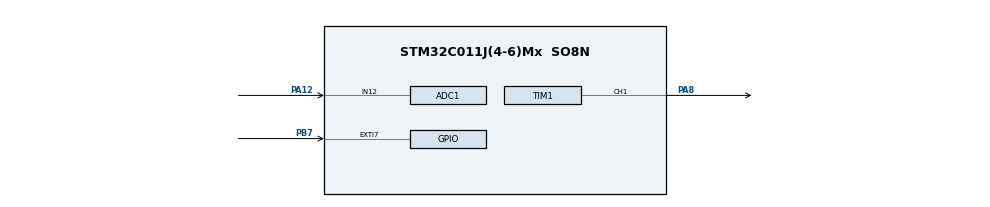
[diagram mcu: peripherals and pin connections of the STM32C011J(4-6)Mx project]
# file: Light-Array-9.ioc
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ADC1.Channel-1\#ChannelRegularConversion=ADC_CHANNEL_12
ADC1.ClockPrescaler=ADC_CLOCK_ASYNC_DIV16
ADC1.ContinuousConvMode=DISABLE
ADC1.DMAContinuousRequests=DISABLE
ADC1.NbrOfConversionFlag=1
ADC1.OffsetNumber-1\#ChannelRegularConversion=ADC_OFFSET_NONE
ADC1.Rank-1\#ChannelRegularConversion=1
ADC1.Resolution=ADC_RESOLUTION_8B
ADC1.SamplingTime-1\#ChannelRegularConversion=ADC_SAMPLINGTIME_COMMON_1
ADC1.SelectedChannel=ADC_CHANNEL_12
ADC1.Sequencer=FULLY_CONFIGURABLE
ADC1.master=1
Dma.Request0=TIM1_CH1
Dma.TIM1_CH1.0.Direction=DMA_MEMORY_TO_PERIPH
Dma.TIM1_CH1.0.EventEnable=DISABLE
Dma.TIM1_CH1.0.Instance=DMA1_Channel1
Dma.TIM1_CH1.0.MemDataAlignment=DMA_MDATAALIGN_HALFWORD
Dma.TIM1_CH1.0.MemInc=DMA_MINC_ENABLE
Dma.TIM1_CH1.0.Mode=DMA_NORMAL
Dma.TIM1_CH1.0.PeriphDataAlignment=DMA_PDATAALIGN_HALFWORD
Dma.TIM1_CH1.0.PeriphInc=DMA_PINC_DISABLE
Dma.TIM1_CH1.0.Polarity=HAL_DMAMUX_REQ_GEN_RISING
Dma.TIM1_CH1.0.Priority=DMA_PRIORITY_LOW
Dma.TIM1_CH1.0.RequestNumber=1
Dma.TIM1_CH1.0.SignalID=NONE
Dma.TIM1_CH1.0.SyncEnable=DISABLE
Dma.TIM1_CH1.0.SyncPolarity=HAL_DMAMUX_SYNC_NO_EVENT
Dma.TIM1_CH1.0.SyncRequestNumber=1
Dma.TIM1_CH1.0.SyncSignalID=NONE
Mcu.Family=STM32C0
Mcu.Name=STM32C011J(4-6)Mx
Mcu.Package=SO8N
NVIC.DMA1_Channel1_IRQn=true\:0\:0\:false\:false\:true\:false\:true\:true
NVIC.EXTI4_15_IRQn=true\:0\:0\:true\:false\:true\:true\:true\:true
PA12\ [PA10].Mode=IN12
PA12\ [PA10].Signal=ADC1_IN12
PA13.Mode=Serial_Wire
PA13.Signal=DEBUG_SWDIO
PA14-BOOT0.Mode=Serial_Wire
PA14-BOOT0.Signal=DEBUG_SWCLK
PA8.Signal=S_TIM1_CH1
PA8__PA11\ [PA9].StandardMode=true
PB7.Signal=GPXTI7
PC14-OSCX_IN\ (PC14)__PB7.StandardMode=true
PC15-OSCX_OUT\ (PC15)__PA14-BOOT0__PB6.StandardMode=true
PF2-NRST__PA0__PA1__PA2.StandardMode=true
ProjectManager.HeapSize=0x200
ProjectManager.StackSize=0x400
ProjectManager.TargetToolchain=STM32CubeIDE
RCC.ADCFreq_Value=48000000
RCC.AHBFreq_Value=48000000
RCC.CortexFreq_Value=48000000
RCC.EXTERNAL_CLOCK_VALUE=12288000
RCC.HCLKFreq_Value=48000000
RCC.HSE_VALUE=8000000
RCC.HSISYSCLKDivider=RCC_HSI_DIV1
RCC.HSI_VALUE=48000000
RCC.LSE_VALUE=32768
RCC.SYSCLKFreq_VALUE=48000000
SH.S_TIM1_CH1.0=TIM1_CH1,PWM Generation1 CH1
TIM1.Channel-PWM\ Generation1\ CH1=TIM_CHANNEL_1
TIM1.Period=60-1
VP_TIM1_VS_ClockSourceINT.Mode=Internal
board=custom

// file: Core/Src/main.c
/* USER CODE BEGIN Header */
/**
  ******************************************************************************
  * @file           : main.c
  * @brief          : Main program body
  ******************************************************************************
  * @attention
  *
  * Copyright (c) 2025 STMicroelectronics.
  * All rights reserved.
  *
  * This software is licensed under terms that can be found in the LICENSE file
  * in the root directory of this software component.
  * If no LICENSE file comes with this software, it is provided AS-IS.
  *
  ******************************************************************************
  */
/* USER CODE END Header */
#include "main.h"

/* USER CODE BEGIN Includes */

#include "lib_WS2812C.h"

/* USER CODE END Includes */

ADC_HandleTypeDef hadc1;
TIM_HandleTypeDef htim1;
DMA_HandleTypeDef hdma_tim1_ch1;

/* USER CODE BEGIN PV */

volatile uint8_t FLAG_BTN = 0;

/* USER CODE END PV */

void SystemClock_Config(void);
static void MX_GPIO_Init(void);
static void MX_DMA_Init(void);
static void MX_TIM1_Init(void);
static void MX_ADC1_Init(void);

/* USER CODE BEGIN 0 */

// ADC is configured as 8 bit (max return value = 255)
uint8_t Read_ADC(void)
{
    HAL_ADC_Start(&hadc1);
    HAL_ADC_PollForConversion(&hadc1, 10);
    uint8_t val = HAL_ADC_GetValue(&hadc1);
    HAL_ADC_Stop(&hadc1);
    return val;
}

/* USER CODE END 0 */

int main(void)
{

  /* MCU Configuration--------------------------------------------------------*/

  /* Reset of all peripherals, Initializes the Flash interface and the Systick. */
  HAL_Init();

  /* Configure the system clock */
  SystemClock_Config();

  /* Initialize all configured peripherals */
  MX_GPIO_Init();
  MX_DMA_Init();
  MX_TIM1_Init();
  MX_ADC1_Init();
  /* USER CODE BEGIN 2 */

  // frame holds the colour data that's sent to the LEDs
  // Edit it to have your desired colours and send it.
  struct Colour frame[NUM_LEDS];
  clear_frame(frame);

  HAL_ADCEx_Calibration_Start(&hadc1);

  /* USER CODE END 2 */

  /* Infinite loop */
  /* USER CODE BEGIN WHILE */
	while (1) {

		// Call each pattern you want in the rotation and clear FLAG_BTN after each one.

		Pattern_SingleColour(frame);
		FLAG_BTN = 0;

		Pattern_CycleRGB(frame);
		FLAG_BTN = 0;

		Pattern_RainbowGradient(frame);
		FLAG_BTN = 0;

		Pattern_RainbowGradientDiag(frame);
		FLAG_BTN = 0;

		Pattern_RandomFade(frame);
		FLAG_BTN = 0;

    /* USER CODE END WHILE */

  }
}

void SystemClock_Config(void)
{
  RCC_OscInitTypeDef RCC_OscInitStruct = {0};
  RCC_ClkInitTypeDef RCC_ClkInitStruct = {0};

  __HAL_FLASH_SET_LATENCY(FLASH_LATENCY_1);

  /** Initializes the RCC Oscillators according to the specified parameters
  * in the RCC_OscInitTypeDef structure.
  */
  RCC_OscInitStruct.OscillatorType = RCC_OSCILLATORTYPE_HSI;
  RCC_OscInitStruct.HSIState = RCC_HSI_ON;
  RCC_OscInitStruct.HSIDiv = RCC_HSI_DIV1;
  RCC_OscInitStruct.HSICalibrationValue = RCC_HSICALIBRATION_DEFAULT;
  if (HAL_RCC_OscConfig(&RCC_OscInitStruct) != HAL_OK)
  {
    Error_Handler();
  }

  /** Initializes the CPU, AHB and APB buses clocks
  */
  RCC_ClkInitStruct.ClockType = RCC_CLOCKTYPE_HCLK|RCC_CLOCKTYPE_SYSCLK
                              |RCC_CLOCKTYPE_PCLK1;
  RCC_ClkInitStruct.SYSCLKSource = RCC_SYSCLKSOURCE_HSI;
  RCC_ClkInitStruct.SYSCLKDivider = RCC_SYSCLK_DIV1;
  RCC_ClkInitStruct.AHBCLKDivider = RCC_HCLK_DIV1;
  RCC_ClkInitStruct.APB1CLKDivider = RCC_APB1_DIV1;

  if (HAL_RCC_ClockConfig(&RCC_ClkInitStruct, FLASH_LATENCY_1) != HAL_OK)
  {
    Error_Handler();
  }
}

static void MX_ADC1_Init(void)
{

  ADC_ChannelConfTypeDef sConfig = {0};

  /** Configure the global features of the ADC (Clock, Resolution, Data Alignment and number of conversion)
  */
  hadc1.Instance = ADC1;
  hadc1.Init.ClockPrescaler = ADC_CLOCK_ASYNC_DIV16;
  hadc1.Init.Resolution = ADC_RESOLUTION_8B;
  hadc1.Init.DataAlign = ADC_DATAALIGN_RIGHT;
  hadc1.Init.ScanConvMode = ADC_SCAN_DISABLE;
  hadc1.Init.EOCSelection = ADC_EOC_SINGLE_CONV;
  hadc1.Init.LowPowerAutoWait = DISABLE;
  hadc1.Init.LowPowerAutoPowerOff = DISABLE;
  hadc1.Init.ContinuousConvMode = DISABLE;
  hadc1.Init.NbrOfConversion = 1;
  hadc1.Init.DiscontinuousConvMode = DISABLE;
  hadc1.Init.ExternalTrigConv = ADC_SOFTWARE_START;
  hadc1.Init.ExternalTrigConvEdge = ADC_EXTERNALTRIGCONVEDGE_NONE;
  hadc1.Init.DMAContinuousRequests = DISABLE;
  hadc1.Init.Overrun = ADC_OVR_DATA_PRESERVED;
  hadc1.Init.SamplingTimeCommon1 = ADC_SAMPLETIME_1CYCLE_5;
  hadc1.Init.SamplingTimeCommon2 = ADC_SAMPLETIME_1CYCLE_5;
  hadc1.Init.OversamplingMode = DISABLE;
  hadc1.Init.TriggerFrequencyMode = ADC_TRIGGER_FREQ_HIGH;
  if (HAL_ADC_Init(&hadc1) != HAL_OK)
  {
    Error_Handler();
  }

  /** Configure Regular Channel
  */
  sConfig.Channel = ADC_CHANNEL_12;
  sConfig.Rank = ADC_REGULAR_RANK_1;
  sConfig.SamplingTime = ADC_SAMPLINGTIME_COMMON_1;
  if (HAL_ADC_ConfigChannel(&hadc1, &sConfig) != HAL_OK)
  {
    Error_Handler();
  }

}

static void MX_TIM1_Init(void)
{

  TIM_ClockConfigTypeDef sClockSourceConfig = {0};
  TIM_MasterConfigTypeDef sMasterConfig = {0};
  TIM_OC_InitTypeDef sConfigOC = {0};
  TIM_BreakDeadTimeConfigTypeDef sBreakDeadTimeConfig = {0};

  htim1.Instance = TIM1;
  htim1.Init.Prescaler = 0;
  htim1.Init.CounterMode = TIM_COUNTERMODE_UP;
  htim1.Init.Period = 60-1;
  htim1.Init.ClockDivision = TIM_CLOCKDIVISION_DIV1;
  htim1.Init.RepetitionCounter = 0;
  htim1.Init.AutoReloadPreload = TIM_AUTORELOAD_PRELOAD_DISABLE;
  if (HAL_TIM_Base_Init(&htim1) != HAL_OK)
  {
    Error_Handler();
  }
  sClockSourceConfig.ClockSource = TIM_CLOCKSOURCE_INTERNAL;
  if (HAL_TIM_ConfigClockSource(&htim1, &sClockSourceConfig) != HAL_OK)
  {
    Error_Handler();
  }
  if (HAL_TIM_PWM_Init(&htim1) != HAL_OK)
  {
    Error_Handler();
  }
  sMasterConfig.MasterOutputTrigger = TIM_TRGO_RESET;
  sMasterConfig.MasterOutputTrigger2 = TIM_TRGO2_RESET;
  sMasterConfig.MasterSlaveMode = TIM_MASTERSLAVEMODE_DISABLE;
  if (HAL_TIMEx_MasterConfigSynchronization(&htim1, &sMasterConfig) != HAL_OK)
  {
    Error_Handler();
  }
  sConfigOC.OCMode = TIM_OCMODE_PWM1;
  sConfigOC.Pulse = 0;
  sConfigOC.OCPolarity = TIM_OCPOLARITY_HIGH;
  sConfigOC.OCNPolarity = TIM_OCNPOLARITY_HIGH;
  sConfigOC.OCFastMode = TIM_OCFAST_DISABLE;
  sConfigOC.OCIdleState = TIM_OCIDLESTATE_RESET;
  sConfigOC.OCNIdleState = TIM_OCNIDLESTATE_RESET;
  if (HAL_TIM_PWM_ConfigChannel(&htim1, &sConfigOC, TIM_CHANNEL_1) != HAL_OK)
  {
    Error_Handler();
  }
  sBreakDeadTimeConfig.OffStateRunMode = TIM_OSSR_DISABLE;
  sBreakDeadTimeConfig.OffStateIDLEMode = TIM_OSSI_DISABLE;
  sBreakDeadTimeConfig.LockLevel = TIM_LOCKLEVEL_OFF;
  sBreakDeadTimeConfig.DeadTime = 0;
  sBreakDeadTimeConfig.BreakState = TIM_BREAK_DISABLE;
  sBreakDeadTimeConfig.BreakPolarity = TIM_BREAKPOLARITY_HIGH;
  sBreakDeadTimeConfig.BreakFilter = 0;
  sBreakDeadTimeConfig.BreakAFMode = TIM_BREAK_AFMODE_INPUT;
  sBreakDeadTimeConfig.Break2State = TIM_BREAK2_DISABLE;
  sBreakDeadTimeConfig.Break2Polarity = TIM_BREAK2POLARITY_HIGH;
  sBreakDeadTimeConfig.Break2Filter = 0;
  sBreakDeadTimeConfig.Break2AFMode = TIM_BREAK_AFMODE_INPUT;
  sBreakDeadTimeConfig.AutomaticOutput = TIM_AUTOMATICOUTPUT_DISABLE;
  if (HAL_TIMEx_ConfigBreakDeadTime(&htim1, &sBreakDeadTimeConfig) != HAL_OK)
  {
    Error_Handler();
  }
  HAL_TIM_MspPostInit(&htim1);

}

static void MX_DMA_Init(void)
{

  /* DMA controller clock enable */
  __HAL_RCC_DMA1_CLK_ENABLE();

  /* DMA interrupt init */
  /* DMA1_Channel1_IRQn interrupt configuration */
  HAL_NVIC_SetPriority(DMA1_Channel1_IRQn, 0, 0);
  HAL_NVIC_EnableIRQ(DMA1_Channel1_IRQn);

}

static void MX_GPIO_Init(void)
{
  GPIO_InitTypeDef GPIO_InitStruct = {0};

  /* GPIO Ports Clock Enable */
  __HAL_RCC_GPIOB_CLK_ENABLE();
  __HAL_RCC_GPIOA_CLK_ENABLE();

  /*Configure GPIO pin : PB7 */
  GPIO_InitStruct.Pin = GPIO_PIN_7;
  GPIO_InitStruct.Mode = GPIO_MODE_IT_RISING;
  GPIO_InitStruct.Pull = GPIO_NOPULL;
  HAL_GPIO_Init(GPIOB, &GPIO_InitStruct);

  /* EXTI interrupt init*/
  HAL_NVIC_SetPriority(EXTI4_15_IRQn, 0, 0);
  HAL_NVIC_EnableIRQ(EXTI4_15_IRQn);

}

/* USER CODE BEGIN 4 */

// Code that triggers when the button interrupt happens
void HAL_GPIO_EXTI_Rising_Callback(uint16_t GPIO_Pin) {

	if (GPIO_Pin == GPIO_PIN_7) {
		FLAG_BTN = 1;
	} else {
		__NOP();
	}
}

/* USER CODE END 4 */

void Error_Handler(void)
{
  __disable_irq();
  while (1)
  {
  }
}
